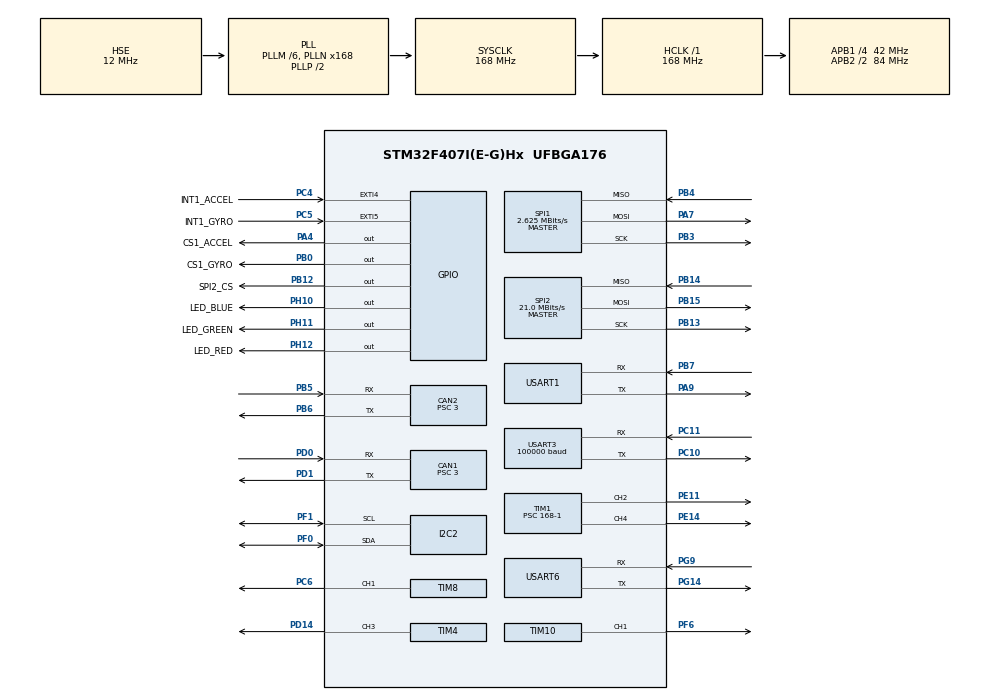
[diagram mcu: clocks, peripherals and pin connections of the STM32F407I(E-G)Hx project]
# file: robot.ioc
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CAN1.ABOM=ENABLE
CAN1.BS1=CAN_BS1_9TQ
CAN1.BS2=CAN_BS2_4TQ
CAN1.CalculateBaudRate=1000000
CAN1.CalculateTimeBit=1000
CAN1.CalculateTimeQuantum=71.42857142857143
CAN1.NART=ENABLE
CAN1.Prescaler=3
CAN2.ABOM=ENABLE
CAN2.BS1=CAN_BS1_9TQ
CAN2.BS2=CAN_BS2_4TQ
CAN2.CalculateBaudRate=1000000
CAN2.CalculateTimeBit=1000
CAN2.CalculateTimeQuantum=71.42857142857143
CAN2.NART=ENABLE
CAN2.Prescaler=3
Dma.Request0=TIM8_CH1
Dma.Request1=USART3_RX
Dma.Request2=USART6_RX
Dma.Request3=USART6_TX
Dma.Request4=USART1_TX
Dma.Request5=USART1_RX
Dma.Request6=TIM1_CH4/TRIG/COM
Dma.TIM1_CH4/TRIG/COM.6.Direction=DMA_PERIPH_TO_MEMORY
Dma.TIM1_CH4/TRIG/COM.6.FIFOMode=DMA_FIFOMODE_DISABLE
Dma.TIM1_CH4/TRIG/COM.6.Instance=DMA2_Stream4
Dma.TIM1_CH4/TRIG/COM.6.MemDataAlignment=DMA_MDATAALIGN_HALFWORD
Dma.TIM1_CH4/TRIG/COM.6.MemInc=DMA_MINC_ENABLE
Dma.TIM1_CH4/TRIG/COM.6.Mode=DMA_NORMAL
Dma.TIM1_CH4/TRIG/COM.6.PeriphDataAlignment=DMA_PDATAALIGN_HALFWORD
Dma.TIM1_CH4/TRIG/COM.6.PeriphInc=DMA_PINC_DISABLE
Dma.TIM1_CH4/TRIG/COM.6.Priority=DMA_PRIORITY_LOW
Dma.TIM8_CH1.0.Direction=DMA_MEMORY_TO_PERIPH
Dma.TIM8_CH1.0.FIFOMode=DMA_FIFOMODE_DISABLE
Dma.TIM8_CH1.0.Instance=DMA2_Stream2
Dma.TIM8_CH1.0.MemDataAlignment=DMA_MDATAALIGN_WORD
Dma.TIM8_CH1.0.MemInc=DMA_MINC_ENABLE
Dma.TIM8_CH1.0.Mode=DMA_NORMAL
Dma.TIM8_CH1.0.PeriphDataAlignment=DMA_PDATAALIGN_WORD
Dma.TIM8_CH1.0.PeriphInc=DMA_PINC_DISABLE
Dma.TIM8_CH1.0.Priority=DMA_PRIORITY_LOW
Dma.USART1_RX.5.Direction=DMA_PERIPH_TO_MEMORY
Dma.USART1_RX.5.FIFOMode=DMA_FIFOMODE_DISABLE
Dma.USART1_RX.5.Instance=DMA2_Stream5
Dma.USART1_RX.5.MemDataAlignment=DMA_MDATAALIGN_BYTE
Dma.USART1_RX.5.MemInc=DMA_MINC_ENABLE
Dma.USART1_RX.5.Mode=DMA_CIRCULAR
Dma.USART1_RX.5.PeriphDataAlignment=DMA_PDATAALIGN_BYTE
Dma.USART1_RX.5.PeriphInc=DMA_PINC_DISABLE
Dma.USART1_RX.5.Priority=DMA_PRIORITY_LOW
Dma.USART1_TX.4.Direction=DMA_MEMORY_TO_PERIPH
Dma.USART1_TX.4.FIFOMode=DMA_FIFOMODE_DISABLE
Dma.USART1_TX.4.Instance=DMA2_Stream7
Dma.USART1_TX.4.MemDataAlignment=DMA_MDATAALIGN_BYTE
Dma.USART1_TX.4.MemInc=DMA_MINC_ENABLE
Dma.USART1_TX.4.Mode=DMA_NORMAL
Dma.USART1_TX.4.PeriphDataAlignment=DMA_PDATAALIGN_BYTE
Dma.USART1_TX.4.PeriphInc=DMA_PINC_DISABLE
Dma.USART1_TX.4.Priority=DMA_PRIORITY_LOW
Dma.USART3_RX.1.Direction=DMA_PERIPH_TO_MEMORY
Dma.USART3_RX.1.FIFOMode=DMA_FIFOMODE_DISABLE
Dma.USART3_RX.1.Instance=DMA1_Stream1
Dma.USART3_RX.1.MemDataAlignment=DMA_MDATAALIGN_BYTE
Dma.USART3_RX.1.MemInc=DMA_MINC_ENABLE
Dma.USART3_RX.1.Mode=DMA_CIRCULAR
Dma.USART3_RX.1.PeriphDataAlignment=DMA_PDATAALIGN_BYTE
Dma.USART3_RX.1.PeriphInc=DMA_PINC_DISABLE
Dma.USART3_RX.1.Priority=DMA_PRIORITY_LOW
Dma.USART6_RX.2.Direction=DMA_PERIPH_TO_MEMORY
Dma.USART6_RX.2.FIFOMode=DMA_FIFOMODE_DISABLE
Dma.USART6_RX.2.Instance=DMA2_Stream1
Dma.USART6_RX.2.MemDataAlignment=DMA_MDATAALIGN_BYTE
Dma.USART6_RX.2.MemInc=DMA_MINC_ENABLE
Dma.USART6_RX.2.Mode=DMA_CIRCULAR
Dma.USART6_RX.2.PeriphDataAlignment=DMA_PDATAALIGN_BYTE
Dma.USART6_RX.2.PeriphInc=DMA_PINC_DISABLE
Dma.USART6_RX.2.Priority=DMA_PRIORITY_LOW
Dma.USART6_TX.3.Direction=DMA_MEMORY_TO_PERIPH
Dma.USART6_TX.3.FIFOMode=DMA_FIFOMODE_DISABLE
Dma.USART6_TX.3.Instance=DMA2_Stream6
Dma.USART6_TX.3.MemDataAlignment=DMA_MDATAALIGN_BYTE
Dma.USART6_TX.3.MemInc=DMA_MINC_ENABLE
Dma.USART6_TX.3.Mode=DMA_NORMAL
Dma.USART6_TX.3.PeriphDataAlignment=DMA_PDATAALIGN_BYTE
Dma.USART6_TX.3.PeriphInc=DMA_PINC_DISABLE
Dma.USART6_TX.3.Priority=DMA_PRIORITY_LOW
FREERTOS.INCLUDE_xTaskGetHandle=1
FREERTOS.Tasks01=defaultTask,24,128,StartDefaultTask,As weak,NULL,Dynamic,NULL,NULL
FREERTOS.configENABLE_FPU=1
I2C2.I2C_Mode=I2C_Standard
Mcu.Family=STM32F4
Mcu.Name=STM32F407I(E-G)Hx
Mcu.Package=UFBGA176
NVIC.CAN1_RX0_IRQn=true\:5\:0\:true\:false\:true\:true\:true\:true\:true
NVIC.CAN1_RX1_IRQn=true\:5\:0\:true\:false\:true\:true\:true\:true\:true
NVIC.CAN2_RX0_IRQn=true\:5\:0\:true\:false\:true\:true\:true\:true\:true
NVIC.CAN2_RX1_IRQn=true\:5\:0\:true\:false\:true\:true\:true\:true\:true
NVIC.DMA1_Stream1_IRQn=true\:5\:0\:false\:false\:true\:true\:false\:true\:true
NVIC.DMA2_Stream1_IRQn=true\:5\:0\:false\:false\:true\:true\:false\:true\:true
NVIC.DMA2_Stream2_IRQn=true\:5\:0\:false\:false\:true\:true\:true\:true\:true
NVIC.DMA2_Stream6_IRQn=true\:6\:0\:true\:false\:true\:true\:false\:true\:true
NVIC.DMA2_Stream7_IRQn=true\:5\:0\:false\:false\:true\:true\:true\:true\:true
NVIC.I2C2_EV_IRQn=true\:7\:0\:true\:false\:true\:true\:true\:true\:true
NVIC.PriorityGroup=NVIC_PRIORITYGROUP_4
NVIC.TIM1_BRK_TIM9_IRQn=true\:5\:0\:true\:false\:true\:true\:true\:true\:true
NVIC.TIM2_IRQn=true\:15\:0\:false\:false\:true\:false\:false\:true\:true
NVIC.TIM3_IRQn=true\:6\:0\:true\:false\:true\:true\:true\:true\:true
NVIC.TIM5_IRQn=true\:5\:0\:true\:false\:true\:true\:true\:true\:true
NVIC.TIM6_DAC_IRQn=true\:6\:0\:true\:false\:true\:true\:true\:true\:true
NVIC.TIM7_IRQn=true\:6\:0\:true\:false\:true\:true\:true\:true\:true
NVIC.TIM8_TRG_COM_TIM14_IRQn=true\:5\:0\:false\:false\:true\:false\:false\:true\:true
NVIC.TIM8_UP_TIM13_IRQn=true\:5\:0\:true\:false\:true\:true\:true\:true\:true
NVIC.TimeBase=TIM2_IRQn
NVIC.TimeBaseIP=TIM2
NVIC.USART1_IRQn=true\:5\:0\:true\:false\:true\:true\:true\:true\:true
NVIC.USART3_IRQn=true\:5\:0\:true\:false\:true\:true\:true\:true\:true
NVIC.USART6_IRQn=true\:6\:0\:true\:false\:true\:true\:false\:true\:true
PA13.Mode=Serial_Wire
PA13.Signal=SYS_JTMS-SWDIO
PA14.Mode=Serial_Wire
PA14.Signal=SYS_JTCK-SWCLK
PA4.GPIO_Label=CS1_ACCEL
PA4.GPIO_PuPd=GPIO_PULLUP
PA4.PinState=GPIO_PIN_SET
PA4.Signal=GPIO_Output
PA7.Mode=Full_Duplex_Master
PA7.Signal=SPI1_MOSI
PA9.Mode=Asynchronous
PA9.Signal=USART1_TX
PB0.GPIO_Label=CS1_GYRO
PB0.GPIO_PuPd=GPIO_PULLUP
PB0.PinState=GPIO_PIN_SET
PB0.Signal=GPIO_Output
PB12.GPIO_Label=SPI2_CS
PB12.Signal=GPIO_Output
PB13.Mode=Full_Duplex_Master
PB13.Signal=SPI2_SCK
PB14.Mode=Full_Duplex_Master
PB14.Signal=SPI2_MISO
PB15.Mode=Full_Duplex_Master
PB15.Signal=SPI2_MOSI
PB3.Mode=Full_Duplex_Master
PB3.Signal=SPI1_SCK
PB4.Mode=Full_Duplex_Master
PB4.Signal=SPI1_MISO
PB5.Mode=CAN_Activate
PB5.Signal=CAN2_RX
PB6.Mode=CAN_Activate
PB6.Signal=CAN2_TX
PB7.Mode=Asynchronous
PB7.Signal=USART1_RX
PC10.Mode=Asynchronous
PC10.Signal=USART3_TX
PC11.Mode=Asynchronous
PC11.Signal=USART3_RX
PC4.GPIO_Label=INT1_ACCEL
PC4.GPIO_PuPd=GPIO_PULLUP
PC4.Signal=GPXTI4
PC5.GPIO_Label=INT1_GYRO
PC5.GPIO_PuPd=GPIO_PULLUP
PC5.Signal=GPXTI5
PC6.Signal=S_TIM8_CH1
PD0.Mode=CAN_Activate
PD0.Signal=CAN1_RX
PD1.Mode=CAN_Activate
PD1.Signal=CAN1_TX
PD14.Signal=S_TIM4_CH3
PE11.Signal=S_TIM1_CH2
PE14.Signal=S_TIM1_CH4
PF0.Mode=I2C
PF0.Signal=I2C2_SDA
PF1.Mode=I2C
PF1.Signal=I2C2_SCL
PF6.Signal=S_TIM10_CH1
PG14.Mode=Asynchronous
PG14.Signal=USART6_TX
PG9.Mode=Asynchronous
PG9.Signal=USART6_RX
PH0-OSC_IN.Mode=HSE-External-Oscillator
PH0-OSC_IN.Signal=RCC_OSC_IN
PH1-OSC_OUT.Mode=HSE-External-Oscillator
PH1-OSC_OUT.Signal=RCC_OSC_OUT
PH10.GPIO_Label=LED_BLUE
PH10.Signal=GPIO_Output
PH11.GPIO_Label=LED_GREEN
PH11.Signal=GPIO_Output
PH12.GPIO_Label=LED_RED
PH12.Signal=GPIO_Output
ProjectManager.HeapSize=0x2000
ProjectManager.StackSize=0x4000
ProjectManager.TargetToolchain=CMake
RCC.48MHZClocksFreq_Value=48000000
RCC.AHBFreq_Value=168000000
RCC.APB1CLKDivider=RCC_HCLK_DIV4
RCC.APB1Freq_Value=42000000
RCC.APB1TimFreq_Value=84000000
RCC.APB2CLKDivider=RCC_HCLK_DIV2
RCC.APB2Freq_Value=84000000
RCC.APB2TimFreq_Value=168000000
RCC.CortexFreq_Value=168000000
RCC.HCLKFreq_Value=168000000
RCC.HSE_VALUE=12000000
RCC.HSI_VALUE=16000000
RCC.LSE_VALUE=32768
RCC.PLLM=6
RCC.PLLN=168
RCC.PLLQ=7
RCC.PLLSourceVirtual=RCC_PLLSOURCE_HSE
RCC.SYSCLKFreq_VALUE=168000000
RCC.SYSCLKSource=RCC_SYSCLKSOURCE_PLLCLK
RCC.VCOOutputFreq_Value=336000000
SH.S_TIM10_CH1.0=TIM10_CH1,PWM Generation1 CH1
SH.S_TIM1_CH2.0=TIM1_CH2,PWM Generation2 CH2
SH.S_TIM1_CH4.0=TIM1_CH4,PWM Generation4 CH4
SH.S_TIM4_CH3.0=TIM4_CH3,PWM Generation3 CH3
SH.S_TIM8_CH1.0=TIM8_CH1,PWM Generation1 CH1
SPI1.BaudRatePrescaler=SPI_BAUDRATEPRESCALER_32
SPI1.CLKPhase=SPI_PHASE_2EDGE
SPI1.CLKPolarity=SPI_POLARITY_HIGH
SPI1.CalculateBaudRate=2.625 MBits/s
SPI1.Direction=SPI_DIRECTION_2LINES
SPI1.Mode=SPI_MODE_MASTER
SPI1.VirtualType=VM_MASTER
SPI2.CalculateBaudRate=21.0 MBits/s
SPI2.Direction=SPI_DIRECTION_2LINES
SPI2.Mode=SPI_MODE_MASTER
SPI2.VirtualType=VM_MASTER
TIM1.Channel-PWM\ Generation2\ CH2=TIM_CHANNEL_2
TIM1.Channel-PWM\ Generation4\ CH4=TIM_CHANNEL_4
TIM1.Period=20000-1
TIM1.Prescaler=168-1
TIM10.Channel=TIM_CHANNEL_1
TIM10.Period=5000-1
TIM3.Period=2000-1
TIM3.Prescaler=4200-1
TIM4.Channel-PWM\ Generation3\ CH3=TIM_CHANNEL_3
TIM4.Period=250-1
TIM4.Prescaler=420-1
TIM5.Period=65535
TIM5.Prescaler=84-1
TIM6.Period=52500-1
TIM6.Prescaler=8-1
TIM7.Period=1000-1
TIM7.Prescaler=84-1
TIM8.Channel-PWM\ Generation1\ CH1=TIM_CHANNEL_1
TIM8.Period=210-1
TIM9.Period=800-1
TIM9.Prescaler=168-1
USART1.VirtualMode=VM_ASYNC
USART3.BaudRate=100000
USART3.Mode=MODE_RX
USART3.VirtualMode=VM_ASYNC
USART6.VirtualMode=VM_ASYNC
VP_CRC_VS_CRC.Mode=CRC_Activate
VP_FREERTOS_VS_CMSIS_V2.Mode=CMSIS_V2
VP_RNG_VS_RNG.Mode=RNG_Activate
VP_SYS_VS_tim2.Mode=TIM2
VP_TIM10_VS_ClockSourceINT.Mode=Enable_Timer
VP_TIM1_VS_ClockSourceINT.Mode=Internal
VP_TIM3_VS_ClockSourceINT.Mode=Internal
VP_TIM4_VS_ClockSourceINT.Mode=Internal
VP_TIM5_VS_ClockSourceINT.Mode=Internal
VP_TIM6_VS_ClockSourceINT.Mode=Enable_Timer
VP_TIM7_VS_ClockSourceINT.Mode=Enable_Timer
VP_TIM8_VS_ClockSourceINT.Mode=Internal
VP_TIM9_VS_ClockSourceINT.Mode=Internal
board=custom

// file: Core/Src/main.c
/* USER CODE BEGIN Header */
/**
  ******************************************************************************
  * @file           : main.c
  * @brief          : Main program body
  ******************************************************************************
  * @attention
  *
  * Copyright (c) 2025 STMicroelectronics.
  * All rights reserved.
  *
  * This software is licensed under terms that can be found in the LICENSE file
  * in the root directory of this software component.
  * If no LICENSE file comes with this software, it is provided AS-IS.
  *
  ******************************************************************************
  */
/* USER CODE END Header */
#include "main.h"
#include "cmsis_os.h"

/* USER CODE BEGIN Includes */
#include "PinyCore.hpp"
/* USER CODE END Includes */

CAN_HandleTypeDef hcan1;
CAN_HandleTypeDef hcan2;

CRC_HandleTypeDef hcrc;

I2C_HandleTypeDef hi2c2;

RNG_HandleTypeDef hrng;

SPI_HandleTypeDef hspi1;
SPI_HandleTypeDef hspi2;

TIM_HandleTypeDef htim1;
TIM_HandleTypeDef htim3;
TIM_HandleTypeDef htim4;
TIM_HandleTypeDef htim5;
TIM_HandleTypeDef htim6;
TIM_HandleTypeDef htim7;
TIM_HandleTypeDef htim8;
TIM_HandleTypeDef htim9;
TIM_HandleTypeDef htim10;
DMA_HandleTypeDef hdma_tim1_ch4_trig_com;
DMA_HandleTypeDef hdma_tim8_ch1;

UART_HandleTypeDef huart1;
UART_HandleTypeDef huart3;
UART_HandleTypeDef huart6;
DMA_HandleTypeDef hdma_usart1_tx;
DMA_HandleTypeDef hdma_usart1_rx;
DMA_HandleTypeDef hdma_usart3_rx;
DMA_HandleTypeDef hdma_usart6_rx;
DMA_HandleTypeDef hdma_usart6_tx;

/* Definitions for defaultTask */
osThreadId_t defaultTaskHandle;
const osThreadAttr_t defaultTask_attributes = {
  .name = "defaultTask",
  .stack_size = 128 * 4,
  .priority = (osPriority_t) osPriorityNormal,
};

void SystemClock_Config(void);
void StartDefaultTask(void *argument);

int main(void)
{

  /* MCU Configuration--------------------------------------------------------*/

  /* Reset of all peripherals, Initializes the Flash interface and the Systick. */
  HAL_Init();

  /* Configure the system clock */
  SystemClock_Config();

  /* Initialize all configured peripherals */
  MX_GPIO_Init();
  MX_DMA_Init();
  MX_TIM1_Init();
  MX_TIM3_Init();
  MX_TIM4_Init();
  MX_TIM5_Init();
  MX_TIM6_Init();
  MX_TIM7_Init();
  MX_TIM8_Init();
  MX_TIM9_Init();
  MX_TIM10_Init();
  MX_SPI1_Init();
  MX_I2C2_Init();
  MX_CAN1_Init();
  MX_CAN2_Init();
  MX_USART1_UART_Init();
  MX_USART3_UART_Init();
  MX_USART6_UART_Init();
  MX_CRC_Init();
  MX_RNG_Init();
  MX_SPI2_Init();
  /* USER CODE BEGIN 2 */
  initPinyCore();
  /* USER CODE END 2 */

  /* Init scheduler */
  osKernelInitialize();

  /* Create the thread(s) */
  /* creation of defaultTask */
  defaultTaskHandle = osThreadNew(StartDefaultTask, NULL, &defaultTask_attributes);

  /* Start scheduler */
  osKernelStart();

  /* We should never get here as control is now taken by the scheduler */

  /* Infinite loop */
  while (1)
  {

  }
}

void SystemClock_Config(void)
{
  RCC_OscInitTypeDef RCC_OscInitStruct = {0};
  RCC_ClkInitTypeDef RCC_ClkInitStruct = {0};

  /** Configure the main internal regulator output voltage
  */
  __HAL_RCC_PWR_CLK_ENABLE();
  __HAL_PWR_VOLTAGESCALING_CONFIG(PWR_REGULATOR_VOLTAGE_SCALE1);

  /** Initializes the RCC Oscillators according to the specified parameters
  * in the RCC_OscInitTypeDef structure.
  */
  RCC_OscInitStruct.OscillatorType = RCC_OSCILLATORTYPE_HSE;
  RCC_OscInitStruct.HSEState = RCC_HSE_ON;
  RCC_OscInitStruct.PLL.PLLState = RCC_PLL_ON;
  RCC_OscInitStruct.PLL.PLLSource = RCC_PLLSOURCE_HSE;
  RCC_OscInitStruct.PLL.PLLM = 6;
  RCC_OscInitStruct.PLL.PLLN = 168;
  RCC_OscInitStruct.PLL.PLLP = RCC_PLLP_DIV2;
  RCC_OscInitStruct.PLL.PLLQ = 7;
  if (HAL_RCC_OscConfig(&RCC_OscInitStruct) != HAL_OK)
  {
    Error_Handler();
  }

  /** Initializes the CPU, AHB and APB buses clocks
  */
  RCC_ClkInitStruct.ClockType = RCC_CLOCKTYPE_HCLK|RCC_CLOCKTYPE_SYSCLK
                              |RCC_CLOCKTYPE_PCLK1|RCC_CLOCKTYPE_PCLK2;
  RCC_ClkInitStruct.SYSCLKSource = RCC_SYSCLKSOURCE_PLLCLK;
  RCC_ClkInitStruct.AHBCLKDivider = RCC_SYSCLK_DIV1;
  RCC_ClkInitStruct.APB1CLKDivider = RCC_HCLK_DIV4;
  RCC_ClkInitStruct.APB2CLKDivider = RCC_HCLK_DIV2;

  if (HAL_RCC_ClockConfig(&RCC_ClkInitStruct, FLASH_LATENCY_5) != HAL_OK)
  {
    Error_Handler();
  }
}

void MX_CAN1_Init(void)
{

  hcan1.Instance = CAN1;
  hcan1.Init.Prescaler = 3;
  hcan1.Init.Mode = CAN_MODE_NORMAL;
  hcan1.Init.SyncJumpWidth = CAN_SJW_1TQ;
  hcan1.Init.TimeSeg1 = CAN_BS1_9TQ;
  hcan1.Init.TimeSeg2 = CAN_BS2_4TQ;
  hcan1.Init.TimeTriggeredMode = DISABLE;
  hcan1.Init.AutoBusOff = ENABLE;
  hcan1.Init.AutoWakeUp = DISABLE;
  hcan1.Init.AutoRetransmission = ENABLE;
  hcan1.Init.ReceiveFifoLocked = DISABLE;
  hcan1.Init.TransmitFifoPriority = DISABLE;
  if (HAL_CAN_Init(&hcan1) != HAL_OK)
  {
    Error_Handler();
  }

}

void MX_CAN2_Init(void)
{

  hcan2.Instance = CAN2;
  hcan2.Init.Prescaler = 3;
  hcan2.Init.Mode = CAN_MODE_NORMAL;
  hcan2.Init.SyncJumpWidth = CAN_SJW_1TQ;
  hcan2.Init.TimeSeg1 = CAN_BS1_9TQ;
  hcan2.Init.TimeSeg2 = CAN_BS2_4TQ;
  hcan2.Init.TimeTriggeredMode = DISABLE;
  hcan2.Init.AutoBusOff = ENABLE;
  hcan2.Init.AutoWakeUp = DISABLE;
  hcan2.Init.AutoRetransmission = ENABLE;
  hcan2.Init.ReceiveFifoLocked = DISABLE;
  hcan2.Init.TransmitFifoPriority = DISABLE;
  if (HAL_CAN_Init(&hcan2) != HAL_OK)
  {
    Error_Handler();
  }

}

void MX_CRC_Init(void)
{

  hcrc.Instance = CRC;
  if (HAL_CRC_Init(&hcrc) != HAL_OK)
  {
    Error_Handler();
  }

}

void MX_I2C2_Init(void)
{

  hi2c2.Instance = I2C2;
  hi2c2.Init.ClockSpeed = 100000;
  hi2c2.Init.DutyCycle = I2C_DUTYCYCLE_2;
  hi2c2.Init.OwnAddress1 = 0;
  hi2c2.Init.AddressingMode = I2C_ADDRESSINGMODE_7BIT;
  hi2c2.Init.DualAddressMode = I2C_DUALADDRESS_DISABLE;
  hi2c2.Init.OwnAddress2 = 0;
  hi2c2.Init.GeneralCallMode = I2C_GENERALCALL_DISABLE;
  hi2c2.Init.NoStretchMode = I2C_NOSTRETCH_DISABLE;
  if (HAL_I2C_Init(&hi2c2) != HAL_OK)
  {
    Error_Handler();
  }

}

void MX_RNG_Init(void)
{

  hrng.Instance = RNG;
  if (HAL_RNG_Init(&hrng) != HAL_OK)
  {
    Error_Handler();
  }

}

void MX_SPI1_Init(void)
{

  /* SPI1 parameter configuration*/
  hspi1.Instance = SPI1;
  hspi1.Init.Mode = SPI_MODE_MASTER;
  hspi1.Init.Direction = SPI_DIRECTION_2LINES;
  hspi1.Init.DataSize = SPI_DATASIZE_8BIT;
  hspi1.Init.CLKPolarity = SPI_POLARITY_HIGH;
  hspi1.Init.CLKPhase = SPI_PHASE_2EDGE;
  hspi1.Init.NSS = SPI_NSS_SOFT;
  hspi1.Init.BaudRatePrescaler = SPI_BAUDRATEPRESCALER_32;
  hspi1.Init.FirstBit = SPI_FIRSTBIT_MSB;
  hspi1.Init.TIMode = SPI_TIMODE_DISABLE;
  hspi1.Init.CRCCalculation = SPI_CRCCALCULATION_DISABLE;
  hspi1.Init.CRCPolynomial = 10;
  if (HAL_SPI_Init(&hspi1) != HAL_OK)
  {
    Error_Handler();
  }

}

void MX_SPI2_Init(void)
{

  /* SPI2 parameter configuration*/
  hspi2.Instance = SPI2;
  hspi2.Init.Mode = SPI_MODE_MASTER;
  hspi2.Init.Direction = SPI_DIRECTION_2LINES;
  hspi2.Init.DataSize = SPI_DATASIZE_8BIT;
  hspi2.Init.CLKPolarity = SPI_POLARITY_LOW;
  hspi2.Init.CLKPhase = SPI_PHASE_1EDGE;
  hspi2.Init.NSS = SPI_NSS_SOFT;
  hspi2.Init.BaudRatePrescaler = SPI_BAUDRATEPRESCALER_2;
  hspi2.Init.FirstBit = SPI_FIRSTBIT_MSB;
  hspi2.Init.TIMode = SPI_TIMODE_DISABLE;
  hspi2.Init.CRCCalculation = SPI_CRCCALCULATION_DISABLE;
  hspi2.Init.CRCPolynomial = 10;
  if (HAL_SPI_Init(&hspi2) != HAL_OK)
  {
    Error_Handler();
  }

}

void MX_TIM1_Init(void)
{

  TIM_ClockConfigTypeDef sClockSourceConfig = {0};
  TIM_MasterConfigTypeDef sMasterConfig = {0};
  TIM_OC_InitTypeDef sConfigOC = {0};
  TIM_BreakDeadTimeConfigTypeDef sBreakDeadTimeConfig = {0};

  htim1.Instance = TIM1;
  htim1.Init.Prescaler = 168-1;
  htim1.Init.CounterMode = TIM_COUNTERMODE_UP;
  htim1.Init.Period = 20000-1;
  htim1.Init.ClockDivision = TIM_CLOCKDIVISION_DIV1;
  htim1.Init.RepetitionCounter = 0;
  htim1.Init.AutoReloadPreload = TIM_AUTORELOAD_PRELOAD_DISABLE;
  if (HAL_TIM_Base_Init(&htim1) != HAL_OK)
  {
    Error_Handler();
  }
  sClockSourceConfig.ClockSource = TIM_CLOCKSOURCE_INTERNAL;
  if (HAL_TIM_ConfigClockSource(&htim1, &sClockSourceConfig) != HAL_OK)
  {
    Error_Handler();
  }
  if (HAL_TIM_PWM_Init(&htim1) != HAL_OK)
  {
    Error_Handler();
  }
  sMasterConfig.MasterOutputTrigger = TIM_TRGO_RESET;
  sMasterConfig.MasterSlaveMode = TIM_MASTERSLAVEMODE_DISABLE;
  if (HAL_TIMEx_MasterConfigSynchronization(&htim1, &sMasterConfig) != HAL_OK)
  {
    Error_Handler();
  }
  sConfigOC.OCMode = TIM_OCMODE_PWM1;
  sConfigOC.Pulse = 0;
  sConfigOC.OCPolarity = TIM_OCPOLARITY_HIGH;
  sConfigOC.OCNPolarity = TIM_OCNPOLARITY_HIGH;
  sConfigOC.OCFastMode = TIM_OCFAST_DISABLE;
  sConfigOC.OCIdleState = TIM_OCIDLESTATE_RESET;
  sConfigOC.OCNIdleState = TIM_OCNIDLESTATE_RESET;
  if (HAL_TIM_PWM_ConfigChannel(&htim1, &sConfigOC, TIM_CHANNEL_2) != HAL_OK)
  {
    Error_Handler();
  }
  if (HAL_TIM_PWM_ConfigChannel(&htim1, &sConfigOC, TIM_CHANNEL_4) != HAL_OK)
  {
    Error_Handler();
  }
  sBreakDeadTimeConfig.OffStateRunMode = TIM_OSSR_DISABLE;
  sBreakDeadTimeConfig.OffStateIDLEMode = TIM_OSSI_DISABLE;
  sBreakDeadTimeConfig.LockLevel = TIM_LOCKLEVEL_OFF;
  sBreakDeadTimeConfig.DeadTime = 0;
  sBreakDeadTimeConfig.BreakState = TIM_BREAK_DISABLE;
  sBreakDeadTimeConfig.BreakPolarity = TIM_BREAKPOLARITY_HIGH;
  sBreakDeadTimeConfig.AutomaticOutput = TIM_AUTOMATICOUTPUT_DISABLE;
  if (HAL_TIMEx_ConfigBreakDeadTime(&htim1, &sBreakDeadTimeConfig) != HAL_OK)
  {
    Error_Handler();
  }
  HAL_TIM_MspPostInit(&htim1);

}

void MX_TIM3_Init(void)
{

  TIM_ClockConfigTypeDef sClockSourceConfig = {0};
  TIM_MasterConfigTypeDef sMasterConfig = {0};

  htim3.Instance = TIM3;
  htim3.Init.Prescaler = 4200-1;
  htim3.Init.CounterMode = TIM_COUNTERMODE_UP;
  htim3.Init.Period = 2000-1;
  htim3.Init.ClockDivision = TIM_CLOCKDIVISION_DIV1;
  htim3.Init.AutoReloadPreload = TIM_AUTORELOAD_PRELOAD_DISABLE;
  if (HAL_TIM_Base_Init(&htim3) != HAL_OK)
  {
    Error_Handler();
  }
  sClockSourceConfig.ClockSource = TIM_CLOCKSOURCE_INTERNAL;
  if (HAL_TIM_ConfigClockSource(&htim3, &sClockSourceConfig) != HAL_OK)
  {
    Error_Handler();
  }
  sMasterConfig.MasterOutputTrigger = TIM_TRGO_RESET;
  sMasterConfig.MasterSlaveMode = TIM_MASTERSLAVEMODE_DISABLE;
  if (HAL_TIMEx_MasterConfigSynchronization(&htim3, &sMasterConfig) != HAL_OK)
  {
    Error_Handler();
  }

}

void MX_TIM4_Init(void)
{

  TIM_ClockConfigTypeDef sClockSourceConfig = {0};
  TIM_MasterConfigTypeDef sMasterConfig = {0};
  TIM_OC_InitTypeDef sConfigOC = {0};

  htim4.Instance = TIM4;
  htim4.Init.Prescaler = 420-1;
  htim4.Init.CounterMode = TIM_COUNTERMODE_UP;
  htim4.Init.Period = 250-1;
  htim4.Init.ClockDivision = TIM_CLOCKDIVISION_DIV1;
  htim4.Init.AutoReloadPreload = TIM_AUTORELOAD_PRELOAD_DISABLE;
  if (HAL_TIM_Base_Init(&htim4) != HAL_OK)
  {
    Error_Handler();
  }
  sClockSourceConfig.ClockSource = TIM_CLOCKSOURCE_INTERNAL;
  if (HAL_TIM_ConfigClockSource(&htim4, &sClockSourceConfig) != HAL_OK)
  {
    Error_Handler();
  }
  if (HAL_TIM_PWM_Init(&htim4) != HAL_OK)
  {
    Error_Handler();
  }
  sMasterConfig.MasterOutputTrigger = TIM_TRGO_RESET;
  sMasterConfig.MasterSlaveMode = TIM_MASTERSLAVEMODE_DISABLE;
  if (HAL_TIMEx_MasterConfigSynchronization(&htim4, &sMasterConfig) != HAL_OK)
  {
    Error_Handler();
  }
  sConfigOC.OCMode = TIM_OCMODE_PWM1;
  sConfigOC.Pulse = 0;
  sConfigOC.OCPolarity = TIM_OCPOLARITY_HIGH;
  sConfigOC.OCFastMode = TIM_OCFAST_DISABLE;
  if (HAL_TIM_PWM_ConfigChannel(&htim4, &sConfigOC, TIM_CHANNEL_3) != HAL_OK)
  {
    Error_Handler();
  }
  HAL_TIM_MspPostInit(&htim4);

}

void MX_TIM5_Init(void)
{

  TIM_ClockConfigTypeDef sClockSourceConfig = {0};
  TIM_MasterConfigTypeDef sMasterConfig = {0};

  htim5.Instance = TIM5;
  htim5.Init.Prescaler = 84-1;
  htim5.Init.CounterMode = TIM_COUNTERMODE_UP;
  htim5.Init.Period = 65535;
  htim5.Init.ClockDivision = TIM_CLOCKDIVISION_DIV1;
  htim5.Init.AutoReloadPreload = TIM_AUTORELOAD_PRELOAD_DISABLE;
  if (HAL_TIM_Base_Init(&htim5) != HAL_OK)
  {
    Error_Handler();
  }
  sClockSourceConfig.ClockSource = TIM_CLOCKSOURCE_INTERNAL;
  if (HAL_TIM_ConfigClockSource(&htim5, &sClockSourceConfig) != HAL_OK)
  {
    Error_Handler();
  }
  sMasterConfig.MasterOutputTrigger = TIM_TRGO_RESET;
  sMasterConfig.MasterSlaveMode = TIM_MASTERSLAVEMODE_DISABLE;
  if (HAL_TIMEx_MasterConfigSynchronization(&htim5, &sMasterConfig) != HAL_OK)
  {
    Error_Handler();
  }

}

void MX_TIM6_Init(void)
{

  TIM_MasterConfigTypeDef sMasterConfig = {0};

  htim6.Instance = TIM6;
  htim6.Init.Prescaler = 8-1;
  htim6.Init.CounterMode = TIM_COUNTERMODE_UP;
  htim6.Init.Period = 52500-1;
  htim6.Init.AutoReloadPreload = TIM_AUTORELOAD_PRELOAD_DISABLE;
  if (HAL_TIM_Base_Init(&htim6) != HAL_OK)
  {
    Error_Handler();
  }
  sMasterConfig.MasterOutputTrigger = TIM_TRGO_RESET;
  sMasterConfig.MasterSlaveMode = TIM_MASTERSLAVEMODE_DISABLE;
  if (HAL_TIMEx_MasterConfigSynchronization(&htim6, &sMasterConfig) != HAL_OK)
  {
    Error_Handler();
  }

}

void MX_TIM7_Init(void)
{

  TIM_MasterConfigTypeDef sMasterConfig = {0};

  htim7.Instance = TIM7;
  htim7.Init.Prescaler = 84-1;
  htim7.Init.CounterMode = TIM_COUNTERMODE_UP;
  htim7.Init.Period = 1000-1;
  htim7.Init.AutoReloadPreload = TIM_AUTORELOAD_PRELOAD_DISABLE;
  if (HAL_TIM_Base_Init(&htim7) != HAL_OK)
  {
    Error_Handler();
  }
  sMasterConfig.MasterOutputTrigger = TIM_TRGO_RESET;
  sMasterConfig.MasterSlaveMode = TIM_MASTERSLAVEMODE_DISABLE;
  if (HAL_TIMEx_MasterConfigSynchronization(&htim7, &sMasterConfig) != HAL_OK)
  {
    Error_Handler();
  }

}

void MX_TIM8_Init(void)
{

  TIM_ClockConfigTypeDef sClockSourceConfig = {0};
  TIM_MasterConfigTypeDef sMasterConfig = {0};
  TIM_OC_InitTypeDef sConfigOC = {0};
  TIM_BreakDeadTimeConfigTypeDef sBreakDeadTimeConfig = {0};

  htim8.Instance = TIM8;
  htim8.Init.Prescaler = 0;
  htim8.Init.CounterMode = TIM_COUNTERMODE_UP;
  htim8.Init.Period = 210-1;
  htim8.Init.ClockDivision = TIM_CLOCKDIVISION_DIV1;
  htim8.Init.RepetitionCounter = 0;
  htim8.Init.AutoReloadPreload = TIM_AUTORELOAD_PRELOAD_DISABLE;
  if (HAL_TIM_Base_Init(&htim8) != HAL_OK)
  {
    Error_Handler();
  }
  sClockSourceConfig.ClockSource = TIM_CLOCKSOURCE_INTERNAL;
  if (HAL_TIM_ConfigClockSource(&htim8, &sClockSourceConfig) != HAL_OK)
  {
    Error_Handler();
  }
  if (HAL_TIM_PWM_Init(&htim8) != HAL_OK)
  {
    Error_Handler();
  }
  sMasterConfig.MasterOutputTrigger = TIM_TRGO_RESET;
  sMasterConfig.MasterSlaveMode = TIM_MASTERSLAVEMODE_DISABLE;
  if (HAL_TIMEx_MasterConfigSynchronization(&htim8, &sMasterConfig) != HAL_OK)
  {
    Error_Handler();
  }
  sConfigOC.OCMode = TIM_OCMODE_PWM1;
  sConfigOC.Pulse = 0;
  sConfigOC.OCPolarity = TIM_OCPOLARITY_HIGH;
  sConfigOC.OCNPolarity = TIM_OCNPOLARITY_HIGH;
  sConfigOC.OCFastMode = TIM_OCFAST_DISABLE;
  sConfigOC.OCIdleState = TIM_OCIDLESTATE_RESET;
  sConfigOC.OCNIdleState = TIM_OCNIDLESTATE_RESET;
  if (HAL_TIM_PWM_ConfigChannel(&htim8, &sConfigOC, TIM_CHANNEL_1) != HAL_OK)
  {
    Error_Handler();
  }
  sBreakDeadTimeConfig.OffStateRunMode = TIM_OSSR_DISABLE;
  sBreakDeadTimeConfig.OffStateIDLEMode = TIM_OSSI_DISABLE;
  sBreakDeadTimeConfig.LockLevel = TIM_LOCKLEVEL_OFF;
  sBreakDeadTimeConfig.DeadTime = 0;
  sBreakDeadTimeConfig.BreakState = TIM_BREAK_DISABLE;
  sBreakDeadTimeConfig.BreakPolarity = TIM_BREAKPOLARITY_HIGH;
  sBreakDeadTimeConfig.AutomaticOutput = TIM_AUTOMATICOUTPUT_DISABLE;
  if (HAL_TIMEx_ConfigBreakDeadTime(&htim8, &sBreakDeadTimeConfig) != HAL_OK)
  {
    Error_Handler();
  }
  HAL_TIM_MspPostInit(&htim8);

}

void MX_TIM9_Init(void)
{

  TIM_ClockConfigTypeDef sClockSourceConfig = {0};

  htim9.Instance = TIM9;
  htim9.Init.Prescaler = 168-1;
  htim9.Init.CounterMode = TIM_COUNTERMODE_UP;
  htim9.Init.Period = 800-1;
  htim9.Init.ClockDivision = TIM_CLOCKDIVISION_DIV1;
  htim9.Init.AutoReloadPreload = TIM_AUTORELOAD_PRELOAD_DISABLE;
  if (HAL_TIM_Base_Init(&htim9) != HAL_OK)
  {
    Error_Handler();
  }
  sClockSourceConfig.ClockSource = TIM_CLOCKSOURCE_INTERNAL;
  if (HAL_TIM_ConfigClockSource(&htim9, &sClockSourceConfig) != HAL_OK)
  {
    Error_Handler();
  }

}

void MX_TIM10_Init(void)
{

  TIM_OC_InitTypeDef sConfigOC = {0};

  htim10.Instance = TIM10;
  htim10.Init.Prescaler = 0;
  htim10.Init.CounterMode = TIM_COUNTERMODE_UP;
  htim10.Init.Period = 5000-1;
  htim10.Init.ClockDivision = TIM_CLOCKDIVISION_DIV1;
  htim10.Init.AutoReloadPreload = TIM_AUTORELOAD_PRELOAD_DISABLE;
  if (HAL_TIM_Base_Init(&htim10) != HAL_OK)
  {
    Error_Handler();
  }
  if (HAL_TIM_PWM_Init(&htim10) != HAL_OK)
  {
    Error_Handler();
  }
  sConfigOC.OCMode = TIM_OCMODE_PWM1;
  sConfigOC.Pulse = 0;
  sConfigOC.OCPolarity = TIM_OCPOLARITY_HIGH;
  sConfigOC.OCFastMode = TIM_OCFAST_DISABLE;
  if (HAL_TIM_PWM_ConfigChannel(&htim10, &sConfigOC, TIM_CHANNEL_1) != HAL_OK)
  {
    Error_Handler();
  }
  HAL_TIM_MspPostInit(&htim10);

}

void MX_USART1_UART_Init(void)
{

  huart1.Instance = USART1;
  huart1.Init.BaudRate = 115200;
  huart1.Init.WordLength = UART_WORDLENGTH_8B;
  huart1.Init.StopBits = UART_STOPBITS_1;
  huart1.Init.Parity = UART_PARITY_NONE;
  huart1.Init.Mode = UART_MODE_TX_RX;
  huart1.Init.HwFlowCtl = UART_HWCONTROL_NONE;
  huart1.Init.OverSampling = UART_OVERSAMPLING_16;
  if (HAL_UART_Init(&huart1) != HAL_OK)
  {
    Error_Handler();
  }

}

void MX_USART3_UART_Init(void)
{

  huart3.Instance = USART3;
  huart3.Init.BaudRate = 100000;
  huart3.Init.WordLength = UART_WORDLENGTH_8B;
  huart3.Init.StopBits = UART_STOPBITS_1;
  huart3.Init.Parity = UART_PARITY_NONE;
  huart3.Init.Mode = UART_MODE_RX;
  huart3.Init.HwFlowCtl = UART_HWCONTROL_NONE;
  huart3.Init.OverSampling = UART_OVERSAMPLING_16;
  if (HAL_UART_Init(&huart3) != HAL_OK)
  {
    Error_Handler();
  }

}

void MX_USART6_UART_Init(void)
{

  huart6.Instance = USART6;
  huart6.Init.BaudRate = 115200;
  huart6.Init.WordLength = UART_WORDLENGTH_8B;
  huart6.Init.StopBits = UART_STOPBITS_1;
  huart6.Init.Parity = UART_PARITY_NONE;
  huart6.Init.Mode = UART_MODE_TX_RX;
  huart6.Init.HwFlowCtl = UART_HWCONTROL_NONE;
  huart6.Init.OverSampling = UART_OVERSAMPLING_16;
  if (HAL_UART_Init(&huart6) != HAL_OK)
  {
    Error_Handler();
  }

}

void MX_DMA_Init(void)
{

  /* DMA controller clock enable */
  __HAL_RCC_DMA2_CLK_ENABLE();
  __HAL_RCC_DMA1_CLK_ENABLE();

  /* DMA interrupt init */
  /* DMA1_Stream1_IRQn interrupt configuration */
  HAL_NVIC_SetPriority(DMA1_Stream1_IRQn, 5, 0);
  HAL_NVIC_EnableIRQ(DMA1_Stream1_IRQn);
  /* DMA2_Stream1_IRQn interrupt configuration */
  HAL_NVIC_SetPriority(DMA2_Stream1_IRQn, 5, 0);
  HAL_NVIC_EnableIRQ(DMA2_Stream1_IRQn);
  /* DMA2_Stream2_IRQn interrupt configuration */
  HAL_NVIC_SetPriority(DMA2_Stream2_IRQn, 5, 0);
  HAL_NVIC_EnableIRQ(DMA2_Stream2_IRQn);
  /* DMA2_Stream6_IRQn interrupt configuration */
  HAL_NVIC_SetPriority(DMA2_Stream6_IRQn, 6, 0);
  HAL_NVIC_EnableIRQ(DMA2_Stream6_IRQn);
  /* DMA2_Stream7_IRQn interrupt configuration */
  HAL_NVIC_SetPriority(DMA2_Stream7_IRQn, 5, 0);
  HAL_NVIC_EnableIRQ(DMA2_Stream7_IRQn);

}

void MX_GPIO_Init(void)
{
  GPIO_InitTypeDef GPIO_InitStruct = {0};

  /* GPIO Ports Clock Enable */
  __HAL_RCC_GPIOB_CLK_ENABLE();
  __HAL_RCC_GPIOG_CLK_ENABLE();
  __HAL_RCC_GPIOA_CLK_ENABLE();
  __HAL_RCC_GPIOD_CLK_ENABLE();
  __HAL_RCC_GPIOC_CLK_ENABLE();
  __HAL_RCC_GPIOF_CLK_ENABLE();
  __HAL_RCC_GPIOH_CLK_ENABLE();
  __HAL_RCC_GPIOE_CLK_ENABLE();

  /*Configure GPIO pin Output Level */
  HAL_GPIO_WritePin(GPIOH, LED_RED_Pin|LED_GREEN_Pin|LED_BLUE_Pin, GPIO_PIN_RESET);

  /*Configure GPIO pin Output Level */
  HAL_GPIO_WritePin(CS1_ACCEL_GPIO_Port, CS1_ACCEL_Pin, GPIO_PIN_SET);

  /*Configure GPIO pin Output Level */
  HAL_GPIO_WritePin(SPI2_CS_GPIO_Port, SPI2_CS_Pin, GPIO_PIN_RESET);

  /*Configure GPIO pin Output Level */
  HAL_GPIO_WritePin(CS1_GYRO_GPIO_Port, CS1_GYRO_Pin, GPIO_PIN_SET);

  /*Configure GPIO pins : LED_RED_Pin LED_GREEN_Pin LED_BLUE_Pin */
  GPIO_InitStruct.Pin = LED_RED_Pin|LED_GREEN_Pin|LED_BLUE_Pin;
  GPIO_InitStruct.Mode = GPIO_MODE_OUTPUT_PP;
  GPIO_InitStruct.Pull = GPIO_NOPULL;
  GPIO_InitStruct.Speed = GPIO_SPEED_FREQ_LOW;
  HAL_GPIO_Init(GPIOH, &GPIO_InitStruct);

  /*Configure GPIO pin : CS1_ACCEL_Pin */
  GPIO_InitStruct.Pin = CS1_ACCEL_Pin;
  GPIO_InitStruct.Mode = GPIO_MODE_OUTPUT_PP;
  GPIO_InitStruct.Pull = GPIO_PULLUP;
  GPIO_InitStruct.Speed = GPIO_SPEED_FREQ_LOW;
  HAL_GPIO_Init(CS1_ACCEL_GPIO_Port, &GPIO_InitStruct);

  /*Configure GPIO pins : INT1_ACCEL_Pin INT1_GYRO_Pin */
  GPIO_InitStruct.Pin = INT1_ACCEL_Pin|INT1_GYRO_Pin;
  GPIO_InitStruct.Mode = GPIO_MODE_IT_RISING;
  GPIO_InitStruct.Pull = GPIO_PULLUP;
  HAL_GPIO_Init(GPIOC, &GPIO_InitStruct);

  /*Configure GPIO pin : SPI2_CS_Pin */
  GPIO_InitStruct.Pin = SPI2_CS_Pin;
  GPIO_InitStruct.Mode = GPIO_MODE_OUTPUT_PP;
  GPIO_InitStruct.Pull = GPIO_NOPULL;
  GPIO_InitStruct.Speed = GPIO_SPEED_FREQ_LOW;
  HAL_GPIO_Init(SPI2_CS_GPIO_Port, &GPIO_InitStruct);

  /*Configure GPIO pin : CS1_GYRO_Pin */
  GPIO_InitStruct.Pin = CS1_GYRO_Pin;
  GPIO_InitStruct.Mode = GPIO_MODE_OUTPUT_PP;
  GPIO_InitStruct.Pull = GPIO_PULLUP;
  GPIO_InitStruct.Speed = GPIO_SPEED_FREQ_LOW;
  HAL_GPIO_Init(CS1_GYRO_GPIO_Port, &GPIO_InitStruct);

}

__weak void StartDefaultTask(void *argument)
{
  for(;;)
  {
    osDelay(1);
  }
}

void HAL_TIM_PeriodElapsedCallback(TIM_HandleTypeDef *htim)
{
  if (htim->Instance == TIM2)
  {
    HAL_IncTick();
  }
}

void Error_Handler(void)
{
  __disable_irq();
  while (1)
  {
  }
}
